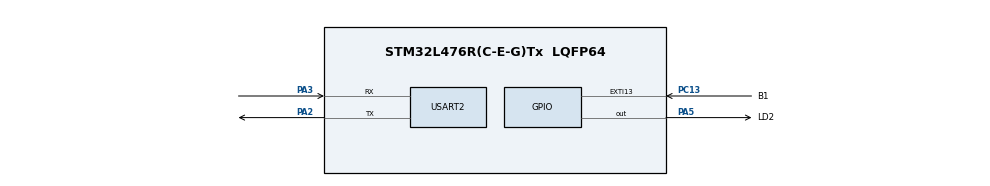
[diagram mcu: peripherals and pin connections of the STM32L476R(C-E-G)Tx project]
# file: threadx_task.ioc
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Dma.Request0=USART2_TX
Dma.Request1=USART2_RX
Dma.USART2_RX.1.Direction=DMA_PERIPH_TO_MEMORY
Dma.USART2_RX.1.Instance=DMA1_Channel6
Dma.USART2_RX.1.MemDataAlignment=DMA_MDATAALIGN_BYTE
Dma.USART2_RX.1.MemInc=DMA_MINC_ENABLE
Dma.USART2_RX.1.Mode=DMA_NORMAL
Dma.USART2_RX.1.PeriphDataAlignment=DMA_PDATAALIGN_BYTE
Dma.USART2_RX.1.PeriphInc=DMA_PINC_DISABLE
Dma.USART2_RX.1.Priority=DMA_PRIORITY_LOW
Dma.USART2_TX.0.Direction=DMA_MEMORY_TO_PERIPH
Dma.USART2_TX.0.Instance=DMA1_Channel7
Dma.USART2_TX.0.MemDataAlignment=DMA_MDATAALIGN_BYTE
Dma.USART2_TX.0.MemInc=DMA_MINC_ENABLE
Dma.USART2_TX.0.Mode=DMA_NORMAL
Dma.USART2_TX.0.PeriphDataAlignment=DMA_PDATAALIGN_BYTE
Dma.USART2_TX.0.PeriphInc=DMA_PINC_DISABLE
Dma.USART2_TX.0.Priority=DMA_PRIORITY_LOW
Mcu.Family=STM32L4
Mcu.Name=STM32L476R(C-E-G)Tx
Mcu.Package=LQFP64
NVIC.DMA1_Channel6_IRQn=true\:0\:0\:false\:false\:true\:true\:false\:true\:true
NVIC.DMA1_Channel7_IRQn=true\:0\:0\:false\:false\:true\:true\:false\:true\:true
NVIC.EXTI15_10_IRQn=true\:0\:0\:false\:false\:true\:false\:true\:true\:true
NVIC.PriorityGroup=NVIC_PRIORITYGROUP_4
NVIC.TIM1_UP_TIM16_IRQn=true\:15\:0\:false\:false\:true\:false\:false\:true\:true
NVIC.TimeBase=TIM1_UP_TIM16_IRQn
NVIC.TimeBaseIP=TIM1
NVIC.USART2_IRQn=true\:0\:0\:false\:false\:true\:false\:true\:true\:true
PA2.Mode=Asynchronous
PA2.Signal=USART2_TX
PA3.Mode=Asynchronous
PA3.Signal=USART2_RX
PA5.GPIO_Label=LD2
PA5.Signal=GPIO_Output
PC13.GPIO_Label=B1
PC13.Signal=GPXTI13
ProjectManager.HeapSize=0x200
ProjectManager.StackSize=0x400
ProjectManager.TargetToolchain=STM32CubeIDE
RCC.HSE_VALUE=8000000
RCC.HSI_VALUE=16000000
RCC.LSE_VALUE=32768
RCC.MSI_VALUE=4000000
RCC.VCOOutputFreq_Value=32000000
STMicroelectronics.X-CUBE-AZRTOS-L4.2.0.0.ThreadXCcRTOSJjThreadXJjCore=true
STMicroelectronics.X-CUBE-AZRTOS-L4.2.0.0.ThreadXCcRTOSJjThreadXJjLowOoPowerOosupport=true
STMicroelectronics.X-CUBE-AZRTOS-L4.2.0.0.ThreadXCcRTOSJjThreadXJjPerformanceInfo=true
STMicroelectronics.X-CUBE-AZRTOS-L4.2.0.0.ThreadXCcRTOSJjThreadXJjTraceXOosupport=true
STMicroelectronics.X-CUBE-AZRTOS-L4.2.0.0_IsAnAzureRtosMw=true
USART2.VirtualMode-Asynchronous=VM_ASYNC
VP_STMicroelectronics.X-CUBE-AZRTOS-L4_VS_RTOSJjThreadX_6.2.0_2.0.0.Mode=RTOSJjThreadX
VP_SYS_VS_tim1.Mode=TIM1
board=custom

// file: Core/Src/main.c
/* USER CODE BEGIN Header */
/**
  ******************************************************************************
  * @file           : main.c
  * @brief          : Main program body
  ******************************************************************************
  * @attention
  *
  * Copyright (c) 2025 STMicroelectronics.
  * All rights reserved.
  *
  * This software is licensed under terms that can be found in the LICENSE file
  * in the root directory of this software component.
  * If no LICENSE file comes with this software, it is provided AS-IS.
  *
  ******************************************************************************
  */
/* USER CODE END Header */
#include "app_threadx.h"
#include "main.h"

UART_HandleTypeDef huart2;

void SystemClock_Config(void);
static void MX_GPIO_Init(void);
static void MX_USART2_UART_Init(void);

int main(void)
{

  /* MCU Configuration--------------------------------------------------------*/

  /* Reset of all peripherals, Initializes the Flash interface and the Systick. */
  HAL_Init();

  /* Configure the system clock */
  SystemClock_Config();

  /* Initialize all configured peripherals */
  MX_GPIO_Init();
  MX_USART2_UART_Init();
  /* USER CODE BEGIN 2 */

  // ThreadX Execution Flow:
  // Mx_ThreadX_Init → _tx_initialize_kernel_enter → tx_application_define → App_ThreadX_Init → <THREAD_NAME>

  // Events (ThreadX):
  // Event flags are kernel objects used for signaling threads that certain events have occurred
  // They are organized into event flag groups, with each group containing 32 flags
  // In an event flag group, each flag is just one bit and represents a different event type...
  // ...(ex: strobe command received, radar speed changed, battery power detected)

  // The two main functions for event flags in ThreadX are tx_event_flags_get and tx_event_flags_set
  // The first function is used to read or wait on event flags, while the second function is used to set (1) or clear (0) event flags
  // Event-driven programming can be enabled in ThreadX by coding the threads in your system to block until certain event flags have been set
  // You can also code the threads in your system to block until ANY or ALL of the event flags that they are waiting on having been set

  // Keep in mind that event flags are level-based and not count-based
  // This means that that are great for checking for state changes, but useless for tallying up how many times a certain event has occurred
  // Also, unless you intend to keep them on, ALWAYS CLEAR EVENT FLAGS WHEN YOU GET THEM!!!

  /* USER CODE END 2 */

  MX_ThreadX_Init();

  /* We should never get here as control is now taken by the scheduler */

  /* Infinite loop */
  while (1)
  {

  }
}

void SystemClock_Config(void)
{
  RCC_OscInitTypeDef RCC_OscInitStruct = {0};
  RCC_ClkInitTypeDef RCC_ClkInitStruct = {0};

  /** Configure the main internal regulator output voltage
  */
  if (HAL_PWREx_ControlVoltageScaling(PWR_REGULATOR_VOLTAGE_SCALE1) != HAL_OK)
  {
    Error_Handler();
  }

  /** Initializes the RCC Oscillators according to the specified parameters
  * in the RCC_OscInitTypeDef structure.
  */
  RCC_OscInitStruct.OscillatorType = RCC_OSCILLATORTYPE_MSI;
  RCC_OscInitStruct.MSIState = RCC_MSI_ON;
  RCC_OscInitStruct.MSICalibrationValue = 0;
  RCC_OscInitStruct.MSIClockRange = RCC_MSIRANGE_6;
  RCC_OscInitStruct.PLL.PLLState = RCC_PLL_NONE;
  if (HAL_RCC_OscConfig(&RCC_OscInitStruct) != HAL_OK)
  {
    Error_Handler();
  }

  /** Initializes the CPU, AHB and APB buses clocks
  */
  RCC_ClkInitStruct.ClockType = RCC_CLOCKTYPE_HCLK|RCC_CLOCKTYPE_SYSCLK
                              |RCC_CLOCKTYPE_PCLK1|RCC_CLOCKTYPE_PCLK2;
  RCC_ClkInitStruct.SYSCLKSource = RCC_SYSCLKSOURCE_MSI;
  RCC_ClkInitStruct.AHBCLKDivider = RCC_SYSCLK_DIV1;
  RCC_ClkInitStruct.APB1CLKDivider = RCC_HCLK_DIV1;
  RCC_ClkInitStruct.APB2CLKDivider = RCC_HCLK_DIV1;

  if (HAL_RCC_ClockConfig(&RCC_ClkInitStruct, FLASH_LATENCY_0) != HAL_OK)
  {
    Error_Handler();
  }
}

static void MX_USART2_UART_Init(void)
{

  huart2.Instance = USART2;
  huart2.Init.BaudRate = 115200;
  huart2.Init.WordLength = UART_WORDLENGTH_8B;
  huart2.Init.StopBits = UART_STOPBITS_1;
  huart2.Init.Parity = UART_PARITY_NONE;
  huart2.Init.Mode = UART_MODE_TX_RX;
  huart2.Init.HwFlowCtl = UART_HWCONTROL_NONE;
  huart2.Init.OverSampling = UART_OVERSAMPLING_16;
  huart2.Init.OneBitSampling = UART_ONE_BIT_SAMPLE_DISABLE;
  huart2.AdvancedInit.AdvFeatureInit = UART_ADVFEATURE_NO_INIT;
  if (HAL_UART_Init(&huart2) != HAL_OK)
  {
    Error_Handler();
  }

}

static void MX_GPIO_Init(void)
{
  GPIO_InitTypeDef GPIO_InitStruct = {0};

  /* GPIO Ports Clock Enable */
  __HAL_RCC_GPIOC_CLK_ENABLE();
  __HAL_RCC_GPIOA_CLK_ENABLE();

  /*Configure GPIO pin Output Level */
  HAL_GPIO_WritePin(LD2_GPIO_Port, LD2_Pin, GPIO_PIN_RESET);

  /*Configure GPIO pin : B1_Pin */
  GPIO_InitStruct.Pin = B1_Pin;
  GPIO_InitStruct.Mode = GPIO_MODE_IT_RISING;
  GPIO_InitStruct.Pull = GPIO_NOPULL;
  HAL_GPIO_Init(B1_GPIO_Port, &GPIO_InitStruct);

  /*Configure GPIO pin : LD2_Pin */
  GPIO_InitStruct.Pin = LD2_Pin;
  GPIO_InitStruct.Mode = GPIO_MODE_OUTPUT_PP;
  GPIO_InitStruct.Pull = GPIO_NOPULL;
  GPIO_InitStruct.Speed = GPIO_SPEED_FREQ_LOW;
  HAL_GPIO_Init(LD2_GPIO_Port, &GPIO_InitStruct);

  /* EXTI interrupt init*/
  HAL_NVIC_SetPriority(EXTI15_10_IRQn, 0, 0);
  HAL_NVIC_EnableIRQ(EXTI15_10_IRQn);

}

void HAL_TIM_PeriodElapsedCallback(TIM_HandleTypeDef *htim)
{
  if (htim->Instance == TIM1) {
    HAL_IncTick();
  }
}

void Error_Handler(void)
{
  __disable_irq();
  while (1)
  {
  }
}
